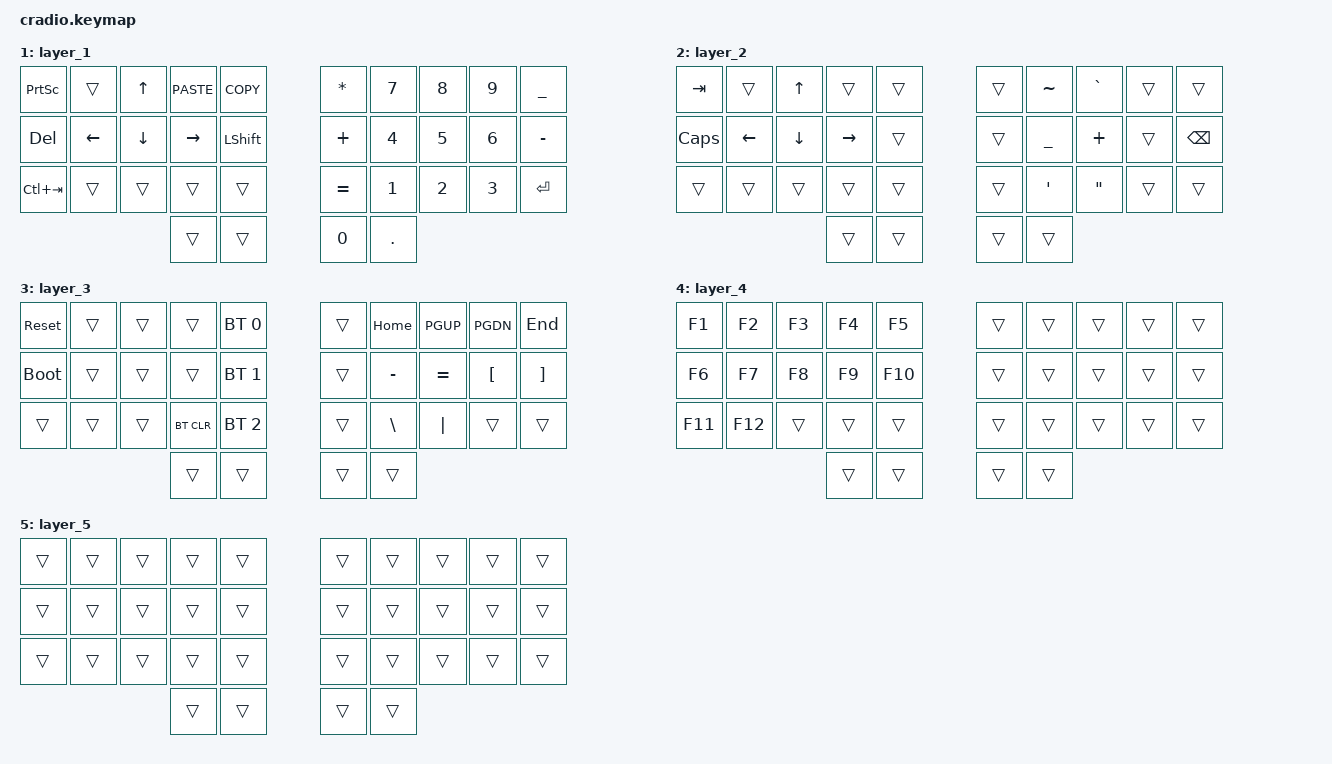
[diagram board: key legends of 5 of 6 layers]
// Copyright (c) 2022 The ZMK Contributors
// SPDX-License-Identifier: MIT

#include <behaviors.dtsi>
#include <dt-bindings/zmk/keys.h>
#include <dt-bindings/zmk/bt.h>

// Home row mods macro
#define HRML(k1,k2,k3,k4) &ht LSHFT k1  &ht LGUI k2  &ht LALT k3  &ht LCTRL k4
#define HRMR(k1,k2,k3,k4) &ht RCTRL k1  &ht LALT k2  &ht RGUI k3  &ht RSHFT k4

/ {
    behaviors {
        ht: hold_tap {
            compatible = "zmk,behavior-hold-tap";
            #binding-cells = <2>;
            flavor = "tap-preferred";
            tapping-term-ms = <220>;
            quick-tap-ms = <150>;
            require-prior-idle-ms = <100>;
            bindings = <&kp>, <&kp>;
        };
    };

//    conditional_layers {
//        compatible = "zmk,conditional-layers";
//        tri_layer {
//            if-layers = <1 2>;
//            then-layer = <3>;
//        };
//    };

    keymap {
        compatible = "zmk,keymap";
        default_layer {
            bindings = <
        //╭──────────┬──────────┬──────────┬──────────┬──────────╮   ╭──────────┬──────────┬──────────┬──────────┬──────────╮
        //│  Q       │  W       │  E       │  R       │  T       │   │  Y       │  U       │  I       │  O       │  P       │
            &kp Q      &kp W      &kp E      &kp R      &kp T          &kp Y      &kp U      &kp I      &kp O      &kp P
        //├──────────┼──────────┼──────────┼──────────┼──────────┤   ├──────────┼──────────┼──────────┼──────────┼──────────┤
        //│  A       │  S       │  D       │  F       │  G       │   │  H       │  J       │  K       │  L       │          │
            HRML(A,        S,         D,         F)      &lt 4 G       &lt 5 H     HRMR(J,        K,         L,        SEMI)
        //├──────────┼──────────┼──────────┼──────────┼──────────┤   ├──────────┼──────────┼──────────┼──────────┼──────────┤
        //│  Z       │  X       │  C       │  V       │  B       │   │  N       │  M       │ , <      │ . >      │ / ?      │
            &kp Z      &kp X      &kp C      &kp V      &kp B          &kp N      &kp M      &kp COMMA  &kp DOT    &kp FSLH
        //╰──────────┴──────────┴──────────┼──────────┼──────────┤   ├──────────┼──────────┼──────────┴──────────┴──────────╯
                               &mt LALT ENTER   &lt 1 &key_repeat     &lt 2 SPACE  &lt 3 ESC
        //                                 ╰──────────┴──────────╯   ╰──────────┴──────────╯
            >;
        };

        layer_1 {
            bindings = <
        //╭──────────┬──────────┬──────────┬──────────┬──────────╮   ╭──────────┬──────────┬──────────┬──────────┬──────────╮
        //│          │          │          │          │          │   │          │          │          │          │          │
           &kp PSCRN  &trans      &kp UP    &kp K_PASTE &kp K_COPY    &kp STAR   &kp N7     &kp N8     &kp N9     &kp UNDER 
        //├──────────┼──────────┼──────────┼──────────┼──────────┤   ├──────────┼──────────┼──────────┼──────────┼──────────┤
        //│          │          │          │          │          │   │          │          │          │          │          │
            &kp DEL    &kp LEFT   &kp DOWN   &kp RIGHT  &kp LSHFT     &kp PLUS   &kp N4     &kp N5     &kp N6     &kp MINUS
        //├──────────┼──────────┼──────────┼──────────┼──────────┤   ├──────────┼──────────┼──────────┼──────────┼──────────┤
        //│          │          │          │          │          │   │          │          │          │          │          │
           &kp LC(TAB) &trans     &trans     &trans     &trans        &kp EQUAL  &kp N1     &kp N2     &kp N3     &kp RET
        //╰──────────┴──────────┴──────────┼──────────┼──────────┤   ├──────────┼──────────┼──────────┴──────────┴──────────╯
                                             &trans     &trans        &kp N0     &kp DOT
        //                                 ╰──────────┴──────────╯   ╰──────────┴──────────╯
            >;
        };

        layer_2 {
            bindings = <
        //╭──────────┬──────────┬──────────┬──────────┬──────────╮   ╭──────────┬──────────┬──────────┬──────────┬──────────╮
        //│          │          │          │          │          │   │          │          │          │          │          │
           &kp TAB    &trans     &kp UP     &trans     &trans         &trans     &kp TILDE  &kp GRAVE  &trans     &trans
        //├──────────┼──────────┼──────────┼──────────┼──────────┤   ├──────────┼──────────┼──────────┼──────────┼──────────┤
        //│          │          │          │          │          │   │          │          │          │          │          │
           &kp CAPS   &kp LEFT   &kp DOWN   &kp RIGHT  &trans         &trans     &kp UNDER  &kp PLUS   &trans     &kp BSPC
        //├──────────┼──────────┼──────────┼──────────┼──────────┤   ├──────────┼──────────┼──────────┼──────────┼──────────┤
        //│          │          │          │          │          │   │          │          │          │          │          │
           &trans     &trans     &trans     &trans     &trans         &trans     &kp SQT     &kp DQT   &trans     &trans
        //╰──────────┴──────────┴──────────┼──────────┼──────────┤   ├──────────┼──────────┼──────────┴──────────┴──────────╯
                                             &trans     &trans         &trans     &trans
        //                                 ╰──────────┴──────────╯   ╰──────────┴──────────╯
            >;
        };

        layer_3 {
            bindings = <
        //╭──────────┬──────────┬──────────┬──────────┬──────────╮   ╭──────────┬──────────┬──────────┬──────────┬──────────╮
        //│ RESET    │          │          │          │PROFILE 0 │   │          │          │          │          │          │
           &sys_reset  &trans     &trans     &trans    &bt BT_SEL 0   &trans     &kp HOME   &kp PGUP   &kp PGDN   &kp END   
        //├──────────┼──────────┼──────────┼──────────┼──────────┤   ├──────────┼──────────┼──────────┼──────────┼──────────┤
        //│BOOTLOADER│          │          │          │PROFILE 1 │   │          │          │          │          │          │
           &bootloader  &trans   &trans     &trans     &bt BT_SEL 1   &trans     &kp MINUS  &kp EQUAL  &kp LBKT   &kp RBKT
        //├──────────┼──────────┼──────────┼──────────┼──────────┤   ├──────────┼──────────┼──────────┼──────────┼──────────┤
        //│          │          │          │ CLEAR BT │PROFILE 2 │   │          │          │          │          │          │
            &trans     &trans     &trans    &bt BT_CLR &bt BT_SEL 2   &trans     &kp BSLH   &kp PIPE     &trans     &trans
        //╰──────────┴──────────┴──────────┼──────────┼──────────┤   ├──────────┼──────────┼──────────┴──────────┴──────────╯
                                             &trans     &trans         &trans     &trans
        //                                 ╰──────────┴──────────╯   ╰──────────┴──────────╯
            >;
        };

        layer_4 {
            bindings = <
        //╭──────────┬──────────┬──────────┬──────────┬──────────╮   ╭──────────┬──────────┬──────────┬──────────┬──────────╮
        //│          │          │          │          │          │   │          │          │          │          │          │
           &kp F1     &kp F2     &kp F3     &kp F4     &kp F5         &trans     &trans     &trans     &trans     &trans
        //├──────────┼──────────┼──────────┼──────────┼──────────┤   ├──────────┼──────────┼──────────┼──────────┼──────────┤
        //│          │          │          │          │          │   │          │          │          │          │          │
           &kp F6     &kp F7     &kp F8     &kp F9     &kp F10        &trans     &trans     &trans     &trans     &trans
        //├──────────┼──────────┼──────────┼──────────┼──────────┤   ├──────────┼──────────┼──────────┼──────────┼──────────┤
        //│          │          │          │          │          │   │          │          │          │          │          │
           &kp F11    &kp F12     &trans     &trans     &trans         &trans     &trans     &trans     &trans     &trans
        //╰──────────┴──────────┴──────────┼──────────┼──────────┤   ├──────────┼──────────┼──────────┴──────────┴──────────╯
                                             &trans     &trans         &trans     &trans
        //                                 ╰──────────┴──────────╯   ╰──────────┴──────────╯
            >;
        };

        layer_5 {
            bindings = <
        //╭──────────┬──────────┬──────────┬──────────┬──────────╮   ╭──────────┬──────────┬──────────┬──────────┬──────────╮
        //│          │          │          │          │          │   │          │          │          │          │          │
           &trans     &trans     &trans     &trans     &trans         &trans     &trans     &trans     &trans     &trans
        //├──────────┼──────────┼──────────┼──────────┼──────────┤   ├──────────┼──────────┼──────────┼──────────┼──────────┤
        //│          │          │          │          │          │   │          │          │          │          │          │
           &trans     &trans     &trans     &trans     &trans         &trans     &trans     &trans     &trans     &trans
        //├──────────┼──────────┼──────────┼──────────┼──────────┤   ├──────────┼──────────┼──────────┼──────────┼──────────┤
        //│          │          │          │          │          │   │          │          │          │          │          │
           &trans     &trans     &trans     &trans     &trans         &trans     &trans     &trans     &trans     &trans
        //╰──────────┴──────────┴──────────┼──────────┼──────────┤   ├──────────┼──────────┼──────────┴──────────┴──────────╯
                                             &trans     &trans         &trans     &trans
        //                                 ╰──────────┴──────────╯   ╰──────────┴──────────╯
            >;
        };
    };
};
